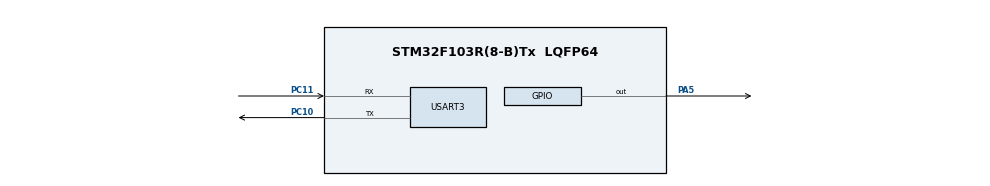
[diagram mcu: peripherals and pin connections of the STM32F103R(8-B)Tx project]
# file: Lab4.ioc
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Mcu.Family=STM32F1
Mcu.Name=STM32F103R(8-B)Tx
Mcu.Package=LQFP64
NVIC.PriorityGroup=NVIC_PRIORITYGROUP_4
NVIC.USART3_IRQn=true\:0\:0\:false\:false\:true\:true\:true
PA13.Mode=Serial_Wire
PA13.Signal=SYS_JTMS-SWDIO
PA14.Mode=Serial_Wire
PA14.Signal=SYS_JTCK-SWCLK
PA5.Signal=GPIO_Output
PC10.Mode=Asynchronous
PC10.Signal=USART3_TX
PC11.Mode=Asynchronous
PC11.Signal=USART3_RX
ProjectManager.HeapSize=0x200
ProjectManager.StackSize=0x400
ProjectManager.TargetToolchain=STM32CubeIDE
RCC.APB1Freq_Value=8000000
RCC.APB2Freq_Value=8000000
TIM4.CounterMode=TIM_COUNTERMODE_DOWN
USART3.VirtualMode=VM_ASYNC
VP_TIM4_VS_ClockSourceINT.Mode=Internal
board=custom

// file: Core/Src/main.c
/* USER CODE BEGIN Header */
/**
  ******************************************************************************
  * @file           : main.c
  * @brief          : Main program body
  ******************************************************************************
  * @attention
  *
  * <h2><center>&copy; Copyright (c) 2020 STMicroelectronics.
  * All rights reserved.</center></h2>
  *
  * This software component is licensed by ST under BSD 3-Clause license,
  * the "License"; You may not use this file except in compliance with the
  * License. You may obtain a copy of the License at:
  *                        opensource.org/licenses/BSD-3-Clause
  *
  ******************************************************************************
  */
/* USER CODE END Header */
#include "main.h"

/* USER CODE BEGIN Includes */
#include "timer.h"
#include "TimingTest.h"
#include "time.h"
#include "CLI.h"
#include <stdio.h>
#include <string.h>
#include <stdbool.h>

/* USER CODE END Includes */

TIM_HandleTypeDef htim4;

UART_HandleTypeDef huart3;

/* USER CODE BEGIN PV */

uint8_t cliBufferTX[56];
uint8_t cliBufferRX[10];
uint8_t save[20];
int j = 0;
int counter = 0;
uint8_t counter_str[20];
const char *CLEAR_SCREEN = "\x1b[2J";
const char *SCROLL_WINDOW = "\x1b[10;r";
const char *GO_TO_SCROLL = "\x1b[10;0H";
const char *GO_TO_TOP = "\x1b[0;0H";
const char *GO_TO_COUNT = "\x1b[0;10H";
const char *HIDE_CURS = "\x1b[?25l";
const char *SHOW_CURS = "\x1b[?25h";
const char *SAVE_CURS = "\x1b[s";
const char *RETURN_CURS = "\x1b[u";

/* USER CODE END PV */

void SystemClock_Config(void);
static void MX_GPIO_Init(void);
static void MX_TIM4_Init(void);
static void MX_USART3_UART_Init(void);

int main(void)
{

  /* MCU Configuration--------------------------------------------------------*/

  /* Reset of all peripherals, Initializes the Flash interface and the Systick. */
  HAL_Init();

  /* Configure the system clock */
  SystemClock_Config();

  /* Initialize all configured peripherals */
  MX_GPIO_Init();
  MX_TIM4_Init();
  MX_USART3_UART_Init();
  /* USER CODE BEGIN 2 */

  //Print out Welcome Message
  printString(CLEAR_SCREEN);
  printString(GO_TO_TOP);
  //printString("\x1b[8;40;100t");
  //printString("\x1b[3;0;0t");
  printString("Welcome to the CLI!\r\n");
  HAL_Delay(2000);

  //Formats the screen to show counter and create a scroll window
  printString(CLEAR_SCREEN);
  printString(GO_TO_TOP);
  printString("counter: ");
  printString(SCROLL_WINDOW);
  printString(GO_TO_SCROLL);

  //printString(goTo(10, 0));

  //Start the process of receiving data
  HAL_UART_Receive_IT(&huart3, cliBufferRX, 1);
  printString("\nEnter a command for the LED:\r\n");
  printString(SAVE_CURS);

  /* USER CODE END 2 */

  /* Infinite loop */
  /* USER CODE BEGIN WHILE */
  while (1)
  {

		//increment counter and display it approx. every 1 second
		HAL_Delay(1000);
		counter++;
		sprintf(counter_str, "%d", counter);
		printString(HIDE_CURS);
		printString(GO_TO_COUNT);
		printString(counter_str);

    /* USER CODE END WHILE */

  }
}

void SystemClock_Config(void)
{
  RCC_OscInitTypeDef RCC_OscInitStruct = {0};
  RCC_ClkInitTypeDef RCC_ClkInitStruct = {0};

  /** Initializes the RCC Oscillators according to the specified parameters
  * in the RCC_OscInitTypeDef structure.
  */
  RCC_OscInitStruct.OscillatorType = RCC_OSCILLATORTYPE_HSI;
  RCC_OscInitStruct.HSIState = RCC_HSI_ON;
  RCC_OscInitStruct.HSICalibrationValue = RCC_HSICALIBRATION_DEFAULT;
  RCC_OscInitStruct.PLL.PLLState = RCC_PLL_NONE;
  if (HAL_RCC_OscConfig(&RCC_OscInitStruct) != HAL_OK)
  {
    Error_Handler();
  }
  /** Initializes the CPU, AHB and APB buses clocks
  */
  RCC_ClkInitStruct.ClockType = RCC_CLOCKTYPE_HCLK|RCC_CLOCKTYPE_SYSCLK
                              |RCC_CLOCKTYPE_PCLK1|RCC_CLOCKTYPE_PCLK2;
  RCC_ClkInitStruct.SYSCLKSource = RCC_SYSCLKSOURCE_HSI;
  RCC_ClkInitStruct.AHBCLKDivider = RCC_SYSCLK_DIV1;
  RCC_ClkInitStruct.APB1CLKDivider = RCC_HCLK_DIV1;
  RCC_ClkInitStruct.APB2CLKDivider = RCC_HCLK_DIV1;

  if (HAL_RCC_ClockConfig(&RCC_ClkInitStruct, FLASH_LATENCY_0) != HAL_OK)
  {
    Error_Handler();
  }
}

static void MX_TIM4_Init(void)
{

  TIM_ClockConfigTypeDef sClockSourceConfig = {0};
  TIM_MasterConfigTypeDef sMasterConfig = {0};

  /* USER CODE BEGIN TIM4_Init 1 */

  __HAL_RCC_TIM4_CLK_ENABLE();

  /* USER CODE END TIM4_Init 1 */
  htim4.Instance = TIM4;
  htim4.Init.Prescaler = 0;
  htim4.Init.CounterMode = TIM_COUNTERMODE_DOWN;
  htim4.Init.Period = 65535;
  htim4.Init.ClockDivision = TIM_CLOCKDIVISION_DIV1;
  htim4.Init.AutoReloadPreload = TIM_AUTORELOAD_PRELOAD_DISABLE;
  if (HAL_TIM_Base_Init(&htim4) != HAL_OK)
  {
    Error_Handler();
  }
  sClockSourceConfig.ClockSource = TIM_CLOCKSOURCE_INTERNAL;
  if (HAL_TIM_ConfigClockSource(&htim4, &sClockSourceConfig) != HAL_OK)
  {
    Error_Handler();
  }
  sMasterConfig.MasterOutputTrigger = TIM_TRGO_RESET;
  sMasterConfig.MasterSlaveMode = TIM_MASTERSLAVEMODE_DISABLE;
  if (HAL_TIMEx_MasterConfigSynchronization(&htim4, &sMasterConfig) != HAL_OK)
  {
    Error_Handler();
  }
  /* USER CODE BEGIN TIM4_Init 2 */

  HAL_TIM_Base_MspInit(&htim4);
  HAL_TIM_Base_Init(&htim4);
  HAL_TIM_Base_Start(&htim4);

  /* USER CODE END TIM4_Init 2 */

}

static void MX_USART3_UART_Init(void)
{

  huart3.Instance = USART3;
  huart3.Init.BaudRate = 115200;
  huart3.Init.WordLength = UART_WORDLENGTH_8B;
  huart3.Init.StopBits = UART_STOPBITS_1;
  huart3.Init.Parity = UART_PARITY_NONE;
  huart3.Init.Mode = UART_MODE_TX_RX;
  huart3.Init.HwFlowCtl = UART_HWCONTROL_NONE;
  huart3.Init.OverSampling = UART_OVERSAMPLING_16;
  if (HAL_UART_Init(&huart3) != HAL_OK)
  {
    Error_Handler();
  }

}

static void MX_GPIO_Init(void)
{
  GPIO_InitTypeDef GPIO_InitStruct = {0};

  /* GPIO Ports Clock Enable */
  __HAL_RCC_GPIOA_CLK_ENABLE();
  __HAL_RCC_GPIOC_CLK_ENABLE();

  /*Configure GPIO pin Output Level */
  HAL_GPIO_WritePin(GPIOA, GPIO_PIN_5, GPIO_PIN_RESET);

  /*Configure GPIO pin : PA5 */
  GPIO_InitStruct.Pin = GPIO_PIN_5;
  GPIO_InitStruct.Mode = GPIO_MODE_OUTPUT_PP;
  GPIO_InitStruct.Pull = GPIO_NOPULL;
  GPIO_InitStruct.Speed = GPIO_SPEED_FREQ_LOW;
  HAL_GPIO_Init(GPIOA, &GPIO_InitStruct);

}

/* USER CODE BEGIN 4 */

void HAL_UART_RxCpltCallback(UART_HandleTypeDef *husart)
{
	counter++;
	printString(RETURN_CURS);
	printString(SHOW_CURS);
	//HAL_UART_Transmit(&huart3, cliBufferRX, 1, 1000);
	copyCharTo(cliBufferRX, save, j);

	//backspace incidence
	if(cliBufferRX[0] == '\b')
	{
		j--;
	}
	else
	{
		j++;
	}

	//when enter is hit execute the command
	if(isCompleteLine(cliBufferRX))
	{
		HAL_UART_Transmit(&huart3, "\r\n", 2, 1000);
		//strcpy((char *)cliBufferTX, save);
		//HAL_UART_Transmit(&huart3, cliBufferTX, strlen((char *)cliBufferTX), 1000);

		executeCommand(save);
		HAL_UART_Transmit(&huart3, "\r\n", 2, 1000);
		j = 0;
		for(int i = 0; i < 20; i++)
		{
			save[i] = NULL;
		}
		printString("\nEnter a command for the LED:\r\n");
	}

	printString(SAVE_CURS);

	while(huart3.gState == HAL_UART_STATE_BUSY_RX){}

	HAL_UART_Receive_IT(&huart3, cliBufferRX, 1);

}

/* USER CODE END 4 */

void Error_Handler(void)
{
}

/************************ (C) COPYRIGHT STMicroelectronics *****END OF FILE****/
